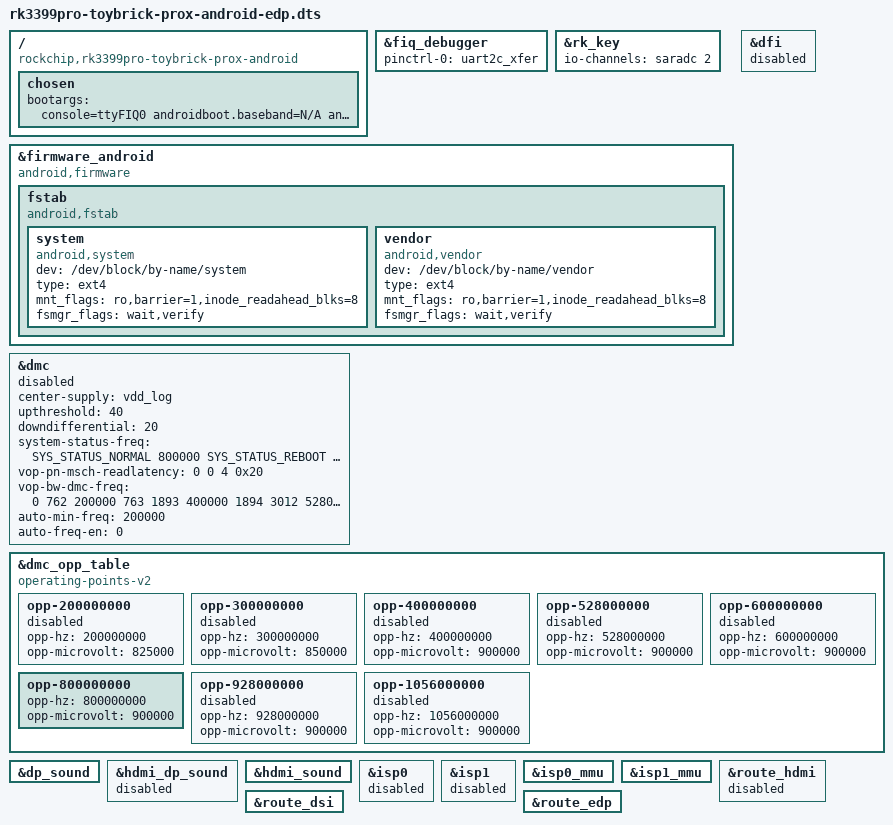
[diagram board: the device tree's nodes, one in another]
/*
 * Copyright (c) 2019 Fuzhou Rockchip Electronics Co., Ltd
 *
 * This file is dual-licensed: you can use it either under the terms
 * of the GPL or the X11 license, at your option. Note that this dual
 * licensing only applies to this file, and not this project as a
 * whole.
 *
 *  a) This file is free software; you can redistribute it and/or
 *     modify it under the terms of the GNU General Public License as
 *     published by the Free Software Foundation; either version 2 of the
 *     License, or (at your option) any later version.
 *
 *     This file is distributed in the hope that it will be useful,
 *     but WITHOUT ANY WARRANTY; without even the implied warranty of
 *     MERCHANTABILITY or FITNESS FOR A PARTICULAR PURPOSE.  See the
 *     GNU General Public License for more details.
 *
 * Or, alternatively,
 *
 *  b) Permission is hereby granted, free of charge, to any person
 *     obtaining a copy of this software and associated documentation
 *     files (the "Software"), to deal in the Software without
 *     restriction, including without limitation the rights to use,
 *     copy, modify, merge, publish, distribute, sublicense, and/or
 *     sell copies of the Software, and to permit persons to whom the
 *     Software is furnished to do so, subject to the following
 *     conditions:
 *
 *     The above copyright notice and this permission notice shall be
 *     included in all copies or substantial portions of the Software.
 *
 *     THE SOFTWARE IS PROVIDED "AS IS", WITHOUT WARRANTY OF ANY KIND,
 *     EXPRESS OR IMPLIED, INCLUDING BUT NOT LIMITED TO THE WARRANTIES
 *     OF MERCHANTABILITY, FITNESS FOR A PARTICULAR PURPOSE AND
 *     NONINFRINGEMENT. IN NO EVENT SHALL THE AUTHORS OR COPYRIGHT
 *     HOLDERS BE LIABLE FOR ANY CLAIM, DAMAGES OR OTHER LIABILITY,
 *     WHETHER IN AN ACTION OF CONTRACT, TORT OR OTHERWISE, ARISING
 *     FROM, OUT OF OR IN CONNECTION WITH THE SOFTWARE OR THE USE OR
 *     OTHER DEALINGS IN THE SOFTWARE.
 */

/dts-v1/;
#include "rk3399pro-toybrick-prox.dtsi"
#include "rk3399-android.dtsi"
#include "rk3399pro-toybrick-edp.dtsi"

/ {
	compatible = "rockchip,rk3399pro-toybrick-prox-android","rockchip,rk3399pro";

    chosen {
        bootargs = "console=ttyFIQ0 androidboot.baseband=N/A androidboot.selinux=permissive androidboot.veritymode=enforcing androidboot.hardware=rk30board androidboot.console=ttyFIQ0 init=/init initrd=0x62000000,0x00800000 earlycon=uart8250,mmio32,0xff1a0000 swiotlb=1";
    };
};

&fiq_debugger {
	pinctrl-0 = <&uart2c_xfer>;
};

&rk_key {
	status = "okay";
	io-channels = <&saradc 2>;
	/delete-node/ power-key;
};

&firmware_android {
    compatible = "android,firmware";
    fstab {
        compatible = "android,fstab";
        system {
            compatible = "android,system";
            dev = "/dev/block/by-name/system";
            type = "ext4";
            mnt_flags = "ro,barrier=1,inode_readahead_blks=8";
            fsmgr_flags = "wait,verify";
        };
        vendor {
            compatible = "android,vendor";
            dev = "/dev/block/by-name/vendor";
            type = "ext4";
            mnt_flags = "ro,barrier=1,inode_readahead_blks=8";
            fsmgr_flags = "wait,verify";
        };
    };
};

&dfi {
	status = "disabled";
};

&dmc {
	status = "disabled";
	center-supply = <&vdd_log>;
	upthreshold = <40>;
	downdifferential = <20>;
	system-status-freq = <
		/*system status         freq(KHz)*/
		SYS_STATUS_NORMAL       800000
		SYS_STATUS_REBOOT       528000
		SYS_STATUS_SUSPEND      200000
		SYS_STATUS_VIDEO_1080P  200000
		SYS_STATUS_VIDEO_4K     600000
		SYS_STATUS_VIDEO_4K_10B 800000
		SYS_STATUS_PERFORMANCE  800000
		SYS_STATUS_BOOST        400000
		SYS_STATUS_DUALVIEW     600000
		SYS_STATUS_ISP          600000
	>;
	vop-pn-msch-readlatency = <
	/* plane_number  readlatency */
		0	0
		4	0x20
	>;
	vop-bw-dmc-freq = <
	/* min_bw(MB/s) max_bw(MB/s) freq(KHz) */
		0       762      200000
		763     1893     400000
		1894    3012     528000
		3013    99999    800000
	>;
	auto-min-freq = <200000>;
	auto-freq-en = <0>;
};

&dmc_opp_table {
	compatible = "operating-points-v2";
	opp-200000000 {
		opp-hz = /bits/ 64 <200000000>;
		opp-microvolt = <825000>;
		status = "disabled";
	};
	opp-300000000 {
		opp-hz = /bits/ 64 <300000000>;
		opp-microvolt = <850000>;
		status = "disabled";
	};
	opp-400000000 {
		opp-hz = /bits/ 64 <400000000>;
		opp-microvolt = <900000>;
		status = "disabled";
	};
	opp-528000000 {
		opp-hz = /bits/ 64 <528000000>;
		opp-microvolt = <900000>;
		status = "disabled";
	};
	opp-600000000 {
		opp-hz = /bits/ 64 <600000000>;
		opp-microvolt = <900000>;
		status = "disabled";
	};
	opp-800000000 {
		opp-hz = /bits/ 64 <800000000>;
		opp-microvolt = <900000>;
	};
	opp-928000000 {
		opp-hz = /bits/ 64 <928000000>;
		opp-microvolt = <900000>;
		status = "disabled";
	};
	opp-1056000000 {
		opp-hz = /bits/ 64 <1056000000>;
		opp-microvolt = <900000>;
		status = "disabled";
	};
};

&dp_sound {
	status = "okay";
};

&hdmi_dp_sound {
	status = "disabled";
};

&hdmi_sound {
	status = "okay";
};

&isp0 {
	status = "disabled";
};

&isp1 {
	status = "disabled";
};

&isp0_mmu {
	status = "okay";
};

&isp1_mmu {
	status = "okay";
};

&route_hdmi {
	status = "disabled";
};

&route_dsi {
        status = "okay";
};

&route_edp {
        status = "okay";
};

